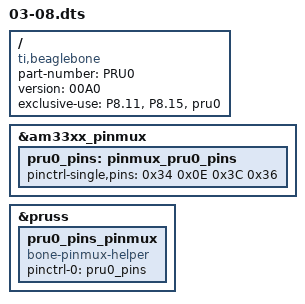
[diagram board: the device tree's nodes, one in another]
/dts-v1/;  
/plugin/;  

/{  
   compatible = "ti,beaglebone", "ti,beaglebone-green", "ti,beaglebone-black";  
   part-number = "PRU0";
   version = "00A0";
   exclusive-use =  
      "P8.11","P8.15","pru0";  
   
   fragment@0 {  
   	target = <&am33xx_pinmux>;  
    	__overlay__ {  
      		pru0_pins: pinmux_pru0_pins {  
      			pinctrl-single,pins = <0x34 0x0E 0x3C 0x36>;  
      		};  
    	};  
   };  
     
   fragment@1 {
        target = <&pruss>;
        __overlay__ {
            pru0_pins_pinmux {
                compatible = "bone-pinmux-helper";
                status = "okay";
                pinctrl-names = "default";
                pinctrl-0 = <&pru0_pins>;
            };
        };
   };

};  
  
